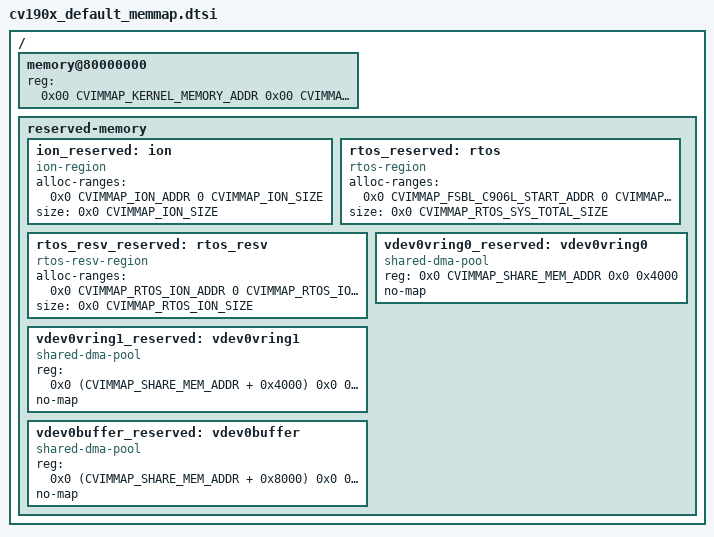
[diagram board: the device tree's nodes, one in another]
/ {
	memory@80000000 {
		device_type = "memory";
		reg = <0x00 CVIMMAP_KERNEL_MEMORY_ADDR 0x00 CVIMMAP_KERNEL_MEMORY_SIZE>;
	};

	reserved-memory {
		#size-cells = <0x2>;
		#address-cells = <0x2>;
		ranges;

#ifndef __UBOOT__
		ion_reserved: ion {
			compatible = "ion-region";
			alloc-ranges = <0x0 CVIMMAP_ION_ADDR 0 CVIMMAP_ION_SIZE>;
			size = <0x0 CVIMMAP_ION_SIZE>;
		};
#endif

		rtos_reserved: rtos {
			compatible = "rtos-region";
			alloc-ranges = <0x0 CVIMMAP_FSBL_C906L_START_ADDR 0 CVIMMAP_RTOS_SYS_TOTAL_SIZE>;
			size = <0x0 CVIMMAP_RTOS_SYS_TOTAL_SIZE>;
		};

		rtos_resv_reserved: rtos_resv {
			compatible = "rtos-resv-region";
			alloc-ranges = <0x0 CVIMMAP_RTOS_ION_ADDR 0 CVIMMAP_RTOS_ION_SIZE>;
			size = <0x0 CVIMMAP_RTOS_ION_SIZE>;
		};

		vdev0vring0_reserved: vdev0vring0 {
			compatible = "shared-dma-pool";
			reg = <0x0 CVIMMAP_SHARE_MEM_ADDR 0x0 0x4000>;
			no-map;
		};

		vdev0vring1_reserved: vdev0vring1 {
			compatible = "shared-dma-pool";
			reg = <0x0 (CVIMMAP_SHARE_MEM_ADDR + 0x4000) 0x0 0x4000>;
			no-map;
		};

		vdev0buffer_reserved: vdev0buffer {
			compatible = "shared-dma-pool";
			reg = <0x0 (CVIMMAP_SHARE_MEM_ADDR + 0x8000) 0x0 0x10000>;
			no-map;
		};

	};
};

